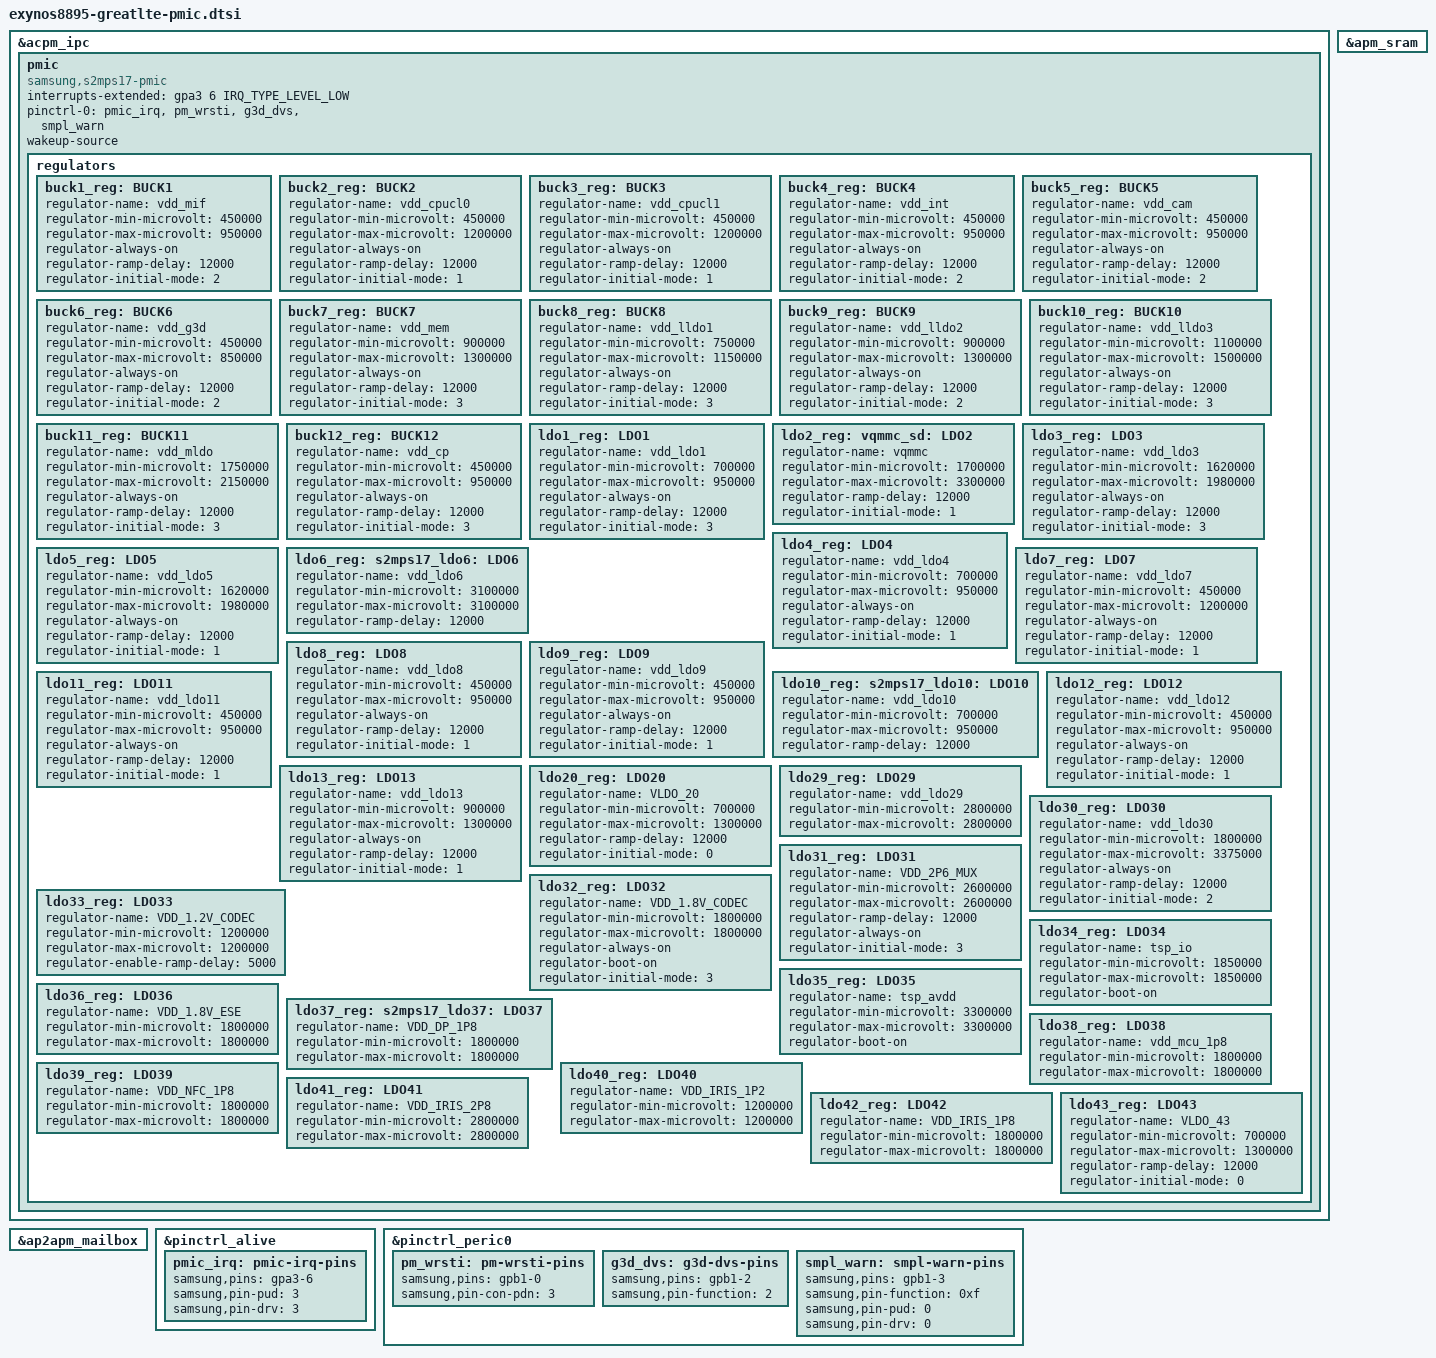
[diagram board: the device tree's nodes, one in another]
// SPDX-License-Identifier: GPL-2.0 OR BSD-3-Clause
/*
 * Samsung Galaxy Note 8 (SM-N950N) PMIC
 */

#include <dt-bindings/interrupt-controller/irq.h>

&acpm_ipc {
	status = "okay";

	pmic {
		compatible = "samsung,s2mps17-pmic";
		interrupts-extended = <&gpa3 6 IRQ_TYPE_LEVEL_LOW>;
		pinctrl-names = "default";
		pinctrl-0 = <&pmic_irq &pm_wrsti &g3d_dvs &smpl_warn>;
		wakeup-source;

		regulators {
			buck1_reg: BUCK1 {
				regulator-name = "vdd_mif";
				regulator-min-microvolt = <450000>;
				regulator-max-microvolt = <950000>;
				regulator-always-on;
				regulator-ramp-delay = <12000>;
				regulator-initial-mode = <2>;
			};

			buck2_reg: BUCK2 {
				regulator-name = "vdd_cpucl0";
				regulator-min-microvolt = <450000>;
				regulator-max-microvolt = <1200000>;
				regulator-always-on;
				regulator-ramp-delay = <12000>;
				regulator-initial-mode = <1>;
			};

			buck3_reg: BUCK3 {
				regulator-name = "vdd_cpucl1";
				regulator-min-microvolt = <450000>;
				regulator-max-microvolt = <1200000>;
				regulator-always-on;
				regulator-ramp-delay = <12000>;
				regulator-initial-mode = <1>;
			};

			buck4_reg: BUCK4 {
				regulator-name = "vdd_int";
				regulator-min-microvolt = <450000>;
				regulator-max-microvolt = <950000>;
				regulator-always-on;
				regulator-ramp-delay = <12000>;
				regulator-initial-mode = <2>;
			};

			buck5_reg: BUCK5 {
				regulator-name = "vdd_cam";
				regulator-min-microvolt = <450000>;
				regulator-max-microvolt = <950000>;
				regulator-always-on;
				regulator-ramp-delay = <12000>;
				regulator-initial-mode = <2>;
			};

			buck6_reg: BUCK6 {
				regulator-name = "vdd_g3d";
				regulator-min-microvolt = <450000>;
				regulator-max-microvolt = <850000>;
				regulator-always-on;
				regulator-ramp-delay = <12000>;
				regulator-initial-mode = <2>;
			};

			buck7_reg: BUCK7 {
				regulator-name = "vdd_mem";
				regulator-min-microvolt = <900000>;
				regulator-max-microvolt = <1300000>;
				regulator-always-on;
				regulator-ramp-delay = <12000>;
				regulator-initial-mode = <3>;
			};

			buck8_reg: BUCK8 {
				regulator-name = "vdd_lldo1";
				regulator-min-microvolt = <750000>;
				regulator-max-microvolt = <1150000>;
				regulator-always-on;
				regulator-ramp-delay = <12000>;
				regulator-initial-mode = <3>;
			};

			buck9_reg: BUCK9 {
				regulator-name = "vdd_lldo2";
				regulator-min-microvolt = <900000>;
				regulator-max-microvolt = <1300000>;
				regulator-always-on;
				regulator-ramp-delay = <12000>;
				regulator-initial-mode = <2>;
			};

			buck10_reg: BUCK10 {
				regulator-name = "vdd_lldo3";
				regulator-min-microvolt = <1100000>;
				regulator-max-microvolt = <1500000>;
				regulator-always-on;
				regulator-ramp-delay = <12000>;
				regulator-initial-mode = <3>;
			};

			buck11_reg: BUCK11 {
				regulator-name = "vdd_mldo";
				regulator-min-microvolt = <1750000>;
				regulator-max-microvolt = <2150000>;
				regulator-always-on;
				regulator-ramp-delay = <12000>;
				regulator-initial-mode = <3>;
			};

			buck12_reg: BUCK12 {
				regulator-name = "vdd_cp";
				regulator-min-microvolt = <450000>;
				regulator-max-microvolt = <950000>;
				regulator-always-on;
				regulator-ramp-delay = <12000>;
				regulator-initial-mode = <3>;
			};

			ldo1_reg: LDO1 {
				regulator-name = "vdd_ldo1";
				regulator-min-microvolt = <700000>;
				regulator-max-microvolt = <950000>;
				regulator-always-on;
				regulator-ramp-delay = <12000>;
				regulator-initial-mode = <3>;
			};

			ldo2_reg: vqmmc_sd: LDO2 {
				regulator-name = "vqmmc";
				regulator-min-microvolt = <1700000>;
				regulator-max-microvolt = <3300000>;
				regulator-ramp-delay = <12000>;
				regulator-initial-mode = <1>;
			};

			ldo3_reg: LDO3 {
				regulator-name = "vdd_ldo3";
				regulator-min-microvolt = <1620000>;
				regulator-max-microvolt = <1980000>;
				regulator-always-on;
				regulator-ramp-delay = <12000>;
				regulator-initial-mode = <3>;
			};

			ldo4_reg: LDO4 {
				regulator-name = "vdd_ldo4";
				regulator-min-microvolt = <700000>;
				regulator-max-microvolt = <950000>;
				regulator-always-on;
				regulator-ramp-delay = <12000>;
				regulator-initial-mode = <1>;
			};

			ldo5_reg: LDO5 {
				regulator-name = "vdd_ldo5";
				regulator-min-microvolt = <1620000>;
				regulator-max-microvolt = <1980000>;
				regulator-always-on;
				regulator-ramp-delay = <12000>;
				regulator-initial-mode = <1>;
			};

			ldo6_reg: s2mps17_ldo6: LDO6 {
				regulator-name = "vdd_ldo6";
				regulator-min-microvolt = <3100000>;
				regulator-max-microvolt = <3100000>;
				regulator-ramp-delay = <12000>;
			};

			ldo7_reg: LDO7 {
				regulator-name = "vdd_ldo7";
				regulator-min-microvolt = <450000>;
				regulator-max-microvolt = <1200000>;
				regulator-always-on;
				regulator-ramp-delay = <12000>;
				regulator-initial-mode = <1>;
			};

			ldo8_reg: LDO8 {
				regulator-name = "vdd_ldo8";
				regulator-min-microvolt = <450000>;
				regulator-max-microvolt = <950000>;
				regulator-always-on;
				regulator-ramp-delay = <12000>;
				regulator-initial-mode = <1>;
			};

			ldo9_reg: LDO9 {
				regulator-name = "vdd_ldo9";
				regulator-min-microvolt = <450000>;
				regulator-max-microvolt = <950000>;
				regulator-always-on;
				regulator-ramp-delay = <12000>;
				regulator-initial-mode = <1>;
			};

			ldo10_reg: s2mps17_ldo10: LDO10 {
				regulator-name = "vdd_ldo10";
				regulator-min-microvolt = <700000>;
				regulator-max-microvolt = <950000>;
				regulator-ramp-delay = <12000>;
			};

			ldo11_reg: LDO11 {
				regulator-name = "vdd_ldo11";
				regulator-min-microvolt = <450000>;
				regulator-max-microvolt = <950000>;
				regulator-always-on;
				regulator-ramp-delay = <12000>;
				regulator-initial-mode = <1>;
			};

			ldo12_reg: LDO12 {
				regulator-name = "vdd_ldo12";
				regulator-min-microvolt = <450000>;
				regulator-max-microvolt = <950000>;
				regulator-always-on;
				regulator-ramp-delay = <12000>;
				regulator-initial-mode = <1>;
			};

			ldo13_reg: LDO13 {
				regulator-name = "vdd_ldo13";
				regulator-min-microvolt = <900000>;
				regulator-max-microvolt = <1300000>;
				regulator-always-on;
				regulator-ramp-delay = <12000>;
				regulator-initial-mode = <1>;
			};

			ldo20_reg: LDO20 {
				regulator-name = "VLDO_20";
				regulator-min-microvolt = <700000>;
				regulator-max-microvolt = <1300000>;
				regulator-ramp-delay = <12000>;
				regulator-initial-mode = <0>;
			};

			ldo29_reg: LDO29 {
				regulator-name = "vdd_ldo29";
				regulator-min-microvolt = <2800000>;
				regulator-max-microvolt = <2800000>;
			};

			ldo30_reg: LDO30 {
				regulator-name = "vdd_ldo30";
				regulator-min-microvolt = <1800000>;
				regulator-max-microvolt = <3375000>;
				regulator-always-on;
				regulator-ramp-delay = <12000>;
				regulator-initial-mode = <2>;
			};

			ldo31_reg: LDO31 {
				regulator-name = "VDD_2P6_MUX";
				regulator-min-microvolt = <2600000>;
				regulator-max-microvolt = <2600000>;
				regulator-ramp-delay = <12000>;
				regulator-always-on;
				regulator-initial-mode = <3>;
			};

			ldo32_reg: LDO32 {
				regulator-name = "VDD_1.8V_CODEC";
				regulator-min-microvolt = <1800000>;
				regulator-max-microvolt = <1800000>;
				regulator-always-on;
				regulator-boot-on;
				regulator-initial-mode = <3>;
			};

			ldo33_reg: LDO33 {
				regulator-name = "VDD_1.2V_CODEC";
				regulator-min-microvolt = <1200000>;
				regulator-max-microvolt = <1200000>;
				regulator-enable-ramp-delay = <5000>;
			};

			ldo34_reg: LDO34 {
				regulator-name = "tsp_io";
				regulator-min-microvolt = <1850000>;
				regulator-max-microvolt = <1850000>;
				regulator-boot-on;
			};

			ldo35_reg: LDO35 {
				regulator-name = "tsp_avdd";
				regulator-min-microvolt = <3300000>;
				regulator-max-microvolt = <3300000>;
				regulator-boot-on;
			};

			ldo36_reg: LDO36 {
				regulator-name = "VDD_1.8V_ESE";
				regulator-min-microvolt = <1800000>;
				regulator-max-microvolt = <1800000>;
			};

			ldo37_reg: s2mps17_ldo37: LDO37 {
				regulator-name = "VDD_DP_1P8";
				regulator-min-microvolt = <1800000>;
				regulator-max-microvolt = <1800000>;
			};

			ldo38_reg: LDO38 {
				regulator-name = "vdd_mcu_1p8";
				regulator-min-microvolt = <1800000>;
				regulator-max-microvolt = <1800000>;
			};

			ldo39_reg: LDO39 {
				regulator-name = "VDD_NFC_1P8";
				regulator-min-microvolt = <1800000>;
				regulator-max-microvolt = <1800000>;
			};

			ldo40_reg: LDO40 {
				regulator-name = "VDD_IRIS_1P2";
				regulator-min-microvolt = <1200000>;
				regulator-max-microvolt = <1200000>;
			};

			ldo41_reg: LDO41 {
				regulator-name = "VDD_IRIS_2P8";
				regulator-min-microvolt = <2800000>;
				regulator-max-microvolt = <2800000>;
			};

			ldo42_reg: LDO42 {
				regulator-name = "VDD_IRIS_1P8";
				regulator-min-microvolt = <1800000>;
				regulator-max-microvolt = <1800000>;
			};

			ldo43_reg: LDO43 {
				regulator-name = "VLDO_43";
				regulator-min-microvolt = <700000>;
				regulator-max-microvolt = <1300000>;
				regulator-ramp-delay = <12000>;
				regulator-initial-mode = <0>;
			};
		};
	};
};

&ap2apm_mailbox {
	status = "okay";
};

&apm_sram {
	status = "okay";
};

&pinctrl_alive {
	pmic_irq: pmic-irq-pins {
		samsung,pins = "gpa3-6";
		samsung,pin-pud = <3>;
		samsung,pin-drv = <3>;
	};
};

&pinctrl_peric0 {
	pm_wrsti: pm-wrsti-pins {
		samsung,pins = "gpb1-0";
		samsung,pin-con-pdn = <3>;
	};

	g3d_dvs: g3d-dvs-pins {
		samsung,pins = "gpb1-2";
		samsung,pin-function = <2>;
	};

	smpl_warn: smpl-warn-pins {
		samsung,pins = "gpb1-3";
		samsung,pin-function = <0xf>;
		samsung,pin-pud = <0>;
		samsung,pin-drv = <0>;
	};
};
